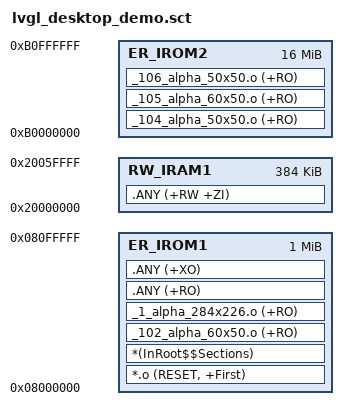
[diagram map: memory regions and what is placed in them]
; *************************************************************
; *** Scatter-Loading Description File generated by uVision ***
; *************************************************************

LR_IROM1 0x08000000 0x00100000  {    ; load region size_region
  ER_IROM1 0x08000000 0x00100000  {  ; load address = execution address
   *.o (RESET, +First)
   *(InRoot$$Sections)
    _102_alpha_60x50.o (+RO)
    _1_alpha_284x226.o (+RO)
   .ANY (+RO)
   .ANY (+XO)
  }
  RW_IRAM1 0x20000000 0x00060000  {  ; RW data
   .ANY (+RW +ZI)
  }
}

LR_IROM2 0xB0000000 0x01000000  {
  ER_IROM2 0xB0000000 0x01000000  {  ; load address = execution address
    _104_alpha_50x50.o (+RO)
    _105_alpha_60x50.o (+RO)
    _106_alpha_50x50.o (+RO)
  }
}
